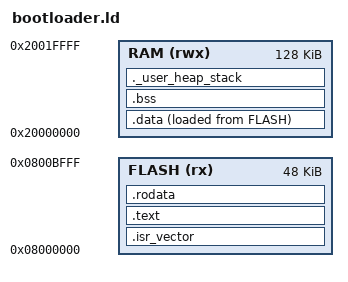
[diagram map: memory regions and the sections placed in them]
/* ========================== Bootloader 链接脚本 ==========================
 * FLASH: 0x08000000 - 0x0800BFFF (48KB, 扇区 0-2)
 * RAM:   0x20000000 - 0x2001FFFF (128KB)
 * 裸机代码，无 C++ 支持，无动态内存分配
 */

ENTRY(Reset_Handler)

MEMORY
{
    FLASH (rx) : ORIGIN = 0x08000000, LENGTH = 48K
    RAM   (rwx): ORIGIN = 0x20000000, LENGTH = 128K
}

_estack = ORIGIN(RAM) + LENGTH(RAM);

SECTIONS
{
    .isr_vector :
    {
        . = ALIGN(4);
        KEEP(*(.isr_vector))
        . = ALIGN(4);
    } >FLASH

    .text :
    {
        . = ALIGN(4);
        *(.text)
        *(.text*)
        *(.glue_7)
        *(.glue_7t)
        *(.eh_frame)
        KEEP(*(.init))
        KEEP(*(.fini))
        . = ALIGN(4);
        _etext = .;
    } >FLASH

    .rodata :
    {
        . = ALIGN(4);
        *(.rodata)
        *(.rodata*)
        . = ALIGN(4);
    } >FLASH

    _sidata = LOADADDR(.data);

    .data :
    {
        . = ALIGN(4);
        _sdata = .;
        *(.data)
        *(.data*)
        . = ALIGN(4);
        _edata = .;
    } >RAM AT>FLASH

    .bss :
    {
        . = ALIGN(4);
        _sbss = .;
        *(.bss)
        *(.bss*)
        *(COMMON)
        . = ALIGN(4);
        _ebss = .;
    } >RAM

    /* 栈保护：确保至少 8KB 剩余空间 */
    ._user_heap_stack :
    {
        . = ALIGN(8);
        . = . + _Min_Stack_Size;
        . = ALIGN(8);
    } >RAM
}

_Min_Stack_Size = 0x2000;  /* 8KB 安全栈 */
